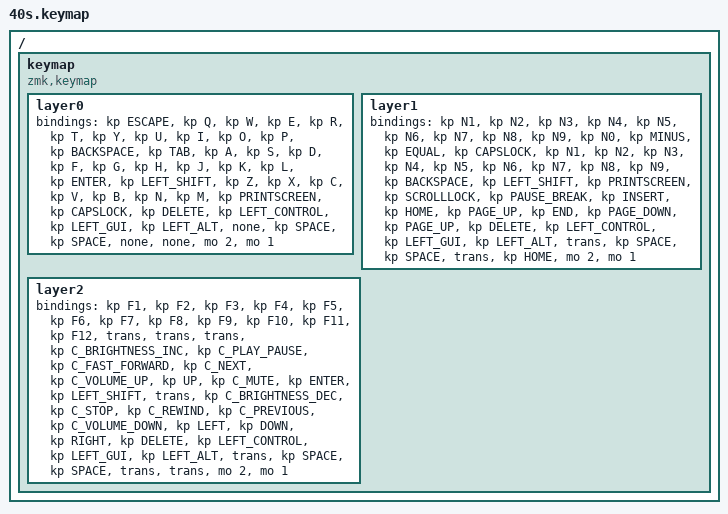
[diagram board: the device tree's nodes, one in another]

  /*
  * Copyright (c) 2020 The ZMK Contributors
  *
  * SPDX-License-Identifier: MIT
  */

  #include <behaviors.dtsi>
  #include <dt-bindings/zmk/keys.h>
  #include <dt-bindings/zmk/bt.h>
  #include <dt-bindings/zmk/ext_power.h>

  / {
    keymap {
      compatible = "zmk,keymap";
  layer0 {
          bindings = <
          &kp ESCAPE &kp Q &kp W &kp E &kp R &kp T &kp Y &kp U &kp I &kp O &kp P &kp BACKSPACE &kp TAB &kp A &kp S &kp D &kp F &kp G &kp H &kp J &kp K &kp L &kp ENTER &kp LEFT_SHIFT &kp Z &kp X &kp C &kp V &kp B &kp N &kp M &kp PRINTSCREEN &kp CAPSLOCK &kp DELETE &kp LEFT_CONTROL &kp LEFT_GUI &kp LEFT_ALT &none &kp SPACE &kp SPACE &none &none &mo 2 &mo 1
          >;
        };layer1 {
          bindings = <
          &kp N1 &kp N2 &kp N3 &kp N4 &kp N5 &kp N6 &kp N7 &kp N8 &kp N9 &kp N0 &kp MINUS &kp EQUAL &kp CAPSLOCK &kp N1 &kp N2 &kp N3 &kp N4 &kp N5 &kp N6 &kp N7 &kp N8 &kp N9 &kp BACKSPACE &kp LEFT_SHIFT &kp PRINTSCREEN &kp SCROLLLOCK &kp PAUSE_BREAK &kp INSERT &kp HOME &kp PAGE_UP &kp END &kp PAGE_DOWN &kp PAGE_UP &kp DELETE &kp LEFT_CONTROL &kp LEFT_GUI &kp LEFT_ALT &trans &kp SPACE &kp SPACE &trans &kp HOME &mo 2 &mo 1
          >;
        };layer2 {
          bindings = <
          &kp F1 &kp F2 &kp F3 &kp F4 &kp F5 &kp F6 &kp F7 &kp F8 &kp F9 &kp F10 &kp F11 &kp F12 &trans &trans &trans &kp C_BRIGHTNESS_INC &kp C_PLAY_PAUSE &kp C_FAST_FORWARD &kp C_NEXT &kp C_VOLUME_UP &kp UP &kp C_MUTE &kp ENTER &kp LEFT_SHIFT &trans &kp C_BRIGHTNESS_DEC &kp C_STOP &kp C_REWIND &kp C_PREVIOUS &kp C_VOLUME_DOWN &kp LEFT &kp DOWN &kp RIGHT &kp DELETE &kp LEFT_CONTROL &kp LEFT_GUI &kp LEFT_ALT &trans &kp SPACE &kp SPACE &trans &trans &mo 2 &mo 1
          >;
        };
    };
  };
  
